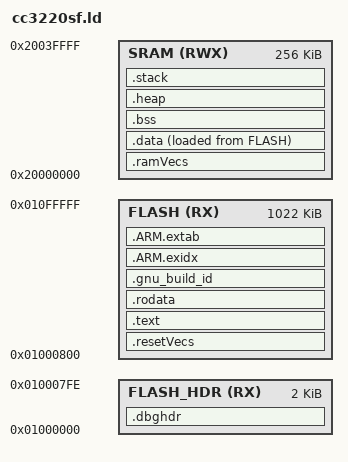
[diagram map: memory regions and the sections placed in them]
STACKSIZE = 0x1000;
HEAP_SIZE = 0x8000;

MEMORY
{
    FLASH_HDR (RX)  : ORIGIN = 0x01000000, LENGTH = 0x7FF
    FLASH     (RX)  : ORIGIN = 0x01000800, LENGTH = 0x0FF800
    SRAM      (RWX) : ORIGIN = 0x20000000, LENGTH = 0x00040000
}

REGION_ALIAS("REGION_HDR", FLASH_HDR);
REGION_ALIAS("REGION_TEXT", FLASH);
REGION_ALIAS("REGION_BSS", SRAM);
REGION_ALIAS("REGION_DATA", SRAM);
REGION_ALIAS("REGION_STACK", SRAM);
REGION_ALIAS("REGION_HEAP", SRAM);
REGION_ALIAS("REGION_ARM_EXIDX", FLASH);
REGION_ALIAS("REGION_ARM_EXTAB", FLASH);

SECTIONS {
    .dbghdr : ALIGN (2048) {
        KEEP (*(.dbghdr))
    } > REGION_HDR

    PROVIDE (_resetVecs_base_address =
        DEFINED(_resetVecs_base_address) ? _resetVecs_base_address : 0x01000800);

    .resetVecs (_resetVecs_base_address) : AT (_resetVecs_base_address) {
        KEEP (*(.resetVecs))
    } > REGION_TEXT

    .ramVecs (NOLOAD) : ALIGN(1024) {
        KEEP (*(.ramVecs))
    } > REGION_DATA

    .text : {
        CREATE_OBJECT_SYMBOLS
        *(.text)
        *(.text.*)
        . = ALIGN(0x4);
        KEEP (*(.ctors))
        . = ALIGN(0x4);
        KEEP (*(.dtors))
        . = ALIGN(0x4);
        __init_array_start = .;
        KEEP (*(.init_array*))
        __init_array_end = .;
        *(.init)
        *(.fini*)
    } > REGION_TEXT AT> REGION_TEXT

    PROVIDE (__etext = .);
    PROVIDE (_etext = .);
    PROVIDE (etext = .);

    .rodata : {
        *(.rodata)
        *(.rodata*)
    } > REGION_TEXT AT> REGION_TEXT

      .gnu_build_id :
      {
        PROVIDE(build_id = .);
        *(.note.gnu.build-id)
      } > REGION_TEXT AT> REGION_TEXT

    .data : ALIGN (4) {
        __data_load__ = LOADADDR (.data);
        __data_start__ = .;
        *(.data)
        *(.data*)
        . = ALIGN (4);
        __data_end__ = .;
    } > REGION_DATA AT> REGION_TEXT

    .ARM.exidx : {
        __exidx_start = .;
        *(.ARM.exidx* .gnu.linkonce.armexidx.*)
        __exidx_end = .;
    } > REGION_ARM_EXIDX AT> REGION_ARM_EXIDX

    .ARM.extab : {
        *(.ARM.extab* .gnu.linkonce.armextab.*)
    } > REGION_ARM_EXTAB AT> REGION_ARM_EXTAB

    .bss : {
        __bss_start__ = .;
        *(.shbss)
        *(.bss)
        *(.bss.*)
        *(COMMON)
        . = ALIGN (4);
        __bss_end__ = .;
    } > REGION_BSS AT> REGION_BSS

    .heap : {
        __heap_start__ = .;
        end = __heap_start__;
        _end = end;
        __end = end;
        . = . + HEAP_SIZE;
        KEEP(*(.heap))
        __heap_end__ = .;
        __HeapLimit = __heap_end__;
    } > REGION_HEAP AT> REGION_HEAP

    .stack (NOLOAD) : ALIGN(0x8) {
        _stack = .;
        __stack = .;
        KEEP(*(.stack))
        . += STACKSIZE;
        _stack_end = .;
        __stack_end = .;
    } > REGION_STACK AT> REGION_STACK
}
